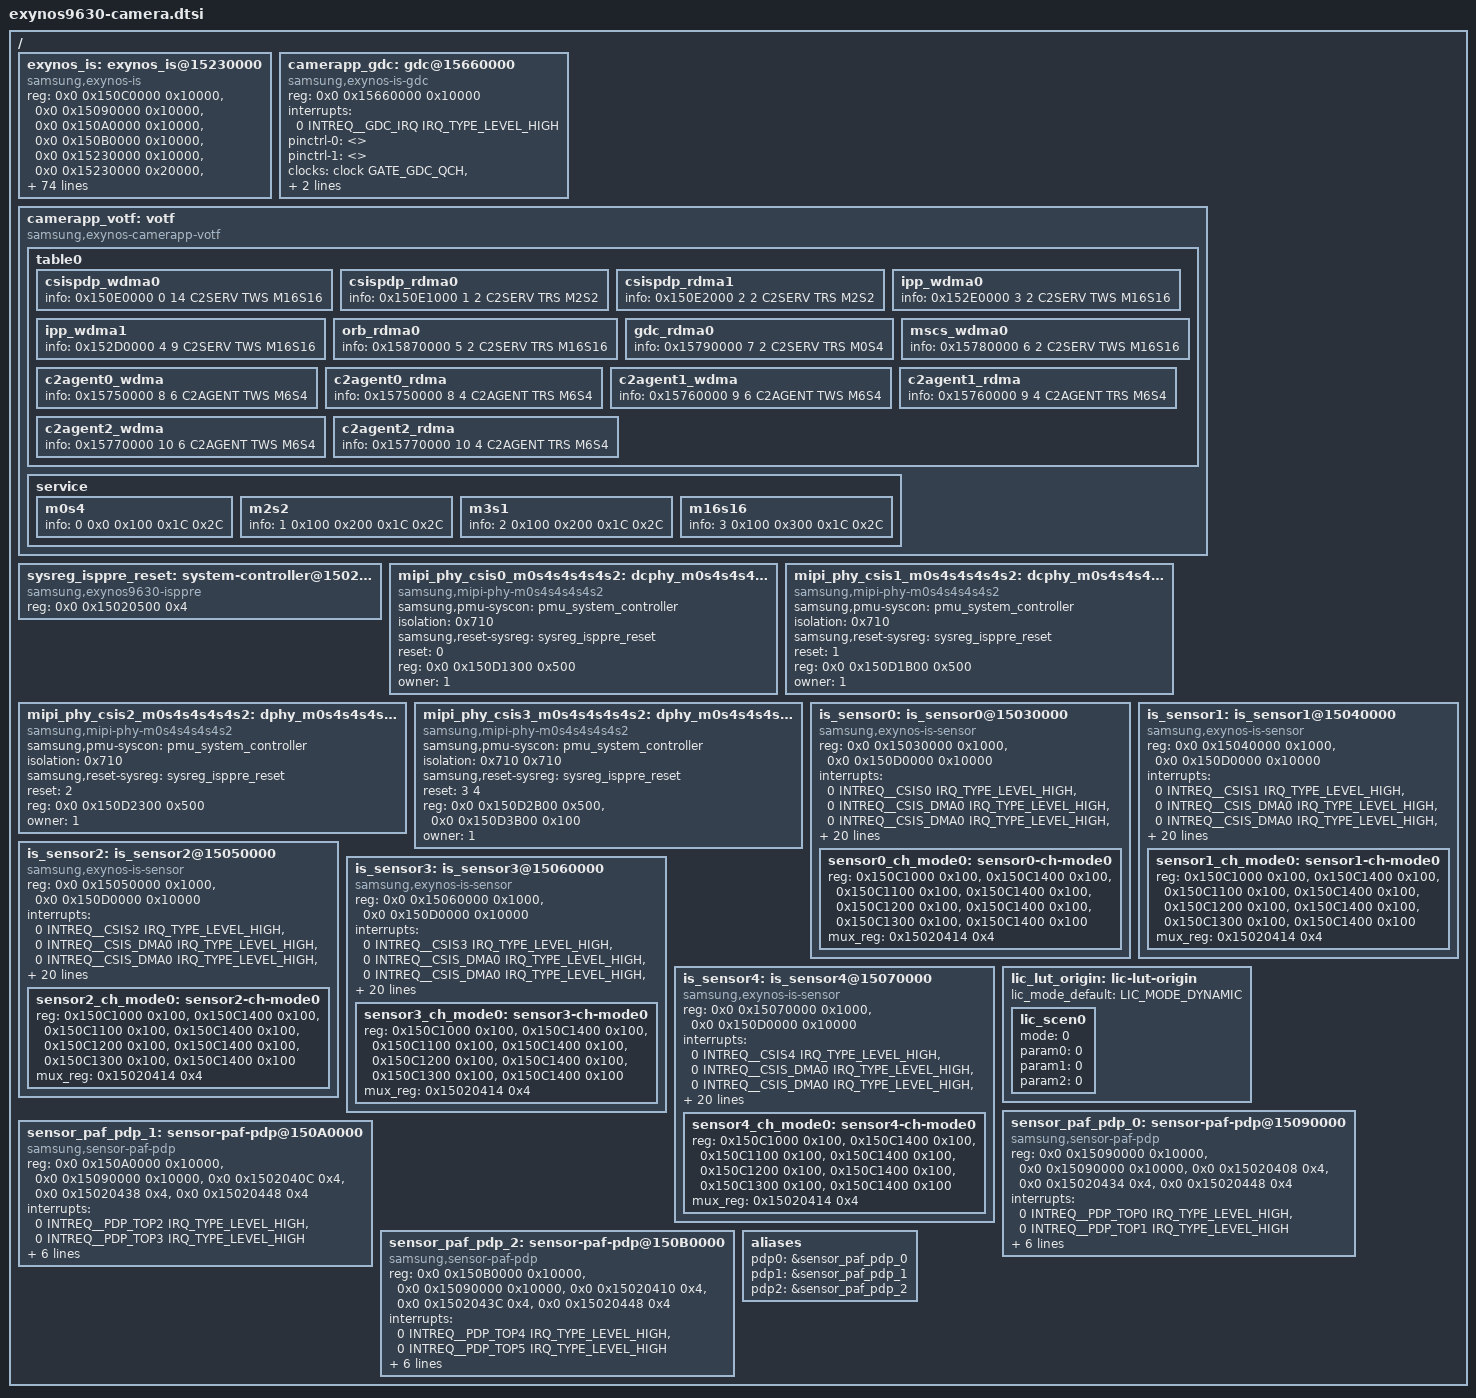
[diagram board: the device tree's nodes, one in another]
/*
 * SAMSUNG EXYNOS9630 SoC camera device tree source
 *
 * Copyright (c) 2019 Samsung Electronics Co., Ltd.
 *		http://www.samsung.com
 *
 * SAMSUNG EXYNOS9630 SoC camera device nodes are listed in this file.
 * EXYNOS9630 based board files can include this file and provide
 * values for board specfic bindings.
 *
 * This program is free software; you can redistribute it and/or modify
 * it under the terms of the GNU General Public License version 2 as
 * published by the Free Software Foundation.
 */

#include <dt-bindings/clock/exynos9630.h>
#include <dt-bindings/interrupt-controller/arm-gic.h>
#include <dt-bindings/interrupt-controller/exynos9630.h>
#include <dt-bindings/camera/exynos_is_dt.h>
#include "exynos9630-pinctrl.dtsi"
#include "exynos9630-sysmmu.dtsi"
#include <dt-bindings/camera/votf.h>

/ {
	exynos_is: exynos_is@15230000 {
		compatible = "samsung,exynos-is";
		reg = <0x0 0x150C0000 0x10000>, /* CSIS DMA  */
			<0x0 0x15090000 0x10000>, /* PDP CORE0 */
			<0x0 0x150A0000 0x10000>, /* PDP CORE1 */
			<0x0 0x150B0000 0x10000>, /* PDP CORE2 */
			<0x0 0x15230000 0x10000>, /* IPP0 */
			<0x0 0x15230000 0x20000>, /* IPP1 */
			<0x0 0x15230000 0x30000>, /* IPP2 */
			<0x0 0x150C0000 0x10000>, /* ZSL/STRIP DMA  */
			<0x0 0x15860000 0x10000>, /* ORBMCH */
			<0x0 0x15430000 0x10000>, /* ITP0 */
			<0x0 0x15840000 0x10000>, /* TNR */
			<0x0 0x15530000 0x10000>, /* DNS0 */
			<0x0 0x15640000 0x10000>, /* MCSC */
			<0x0 0x15360000 0x10000>; /* CLAHE */
		interrupts = <0 INTREQ__IPP_CH0_0 IRQ_TYPE_LEVEL_HIGH>,	/* IPP0_0 */
			<0 INTREQ__IPP_CH0_1 IRQ_TYPE_LEVEL_HIGH>,			/* IPP0_1 */
			<0 INTREQ__ORBMCH IRQ_TYPE_LEVEL_HIGH>,				/* ORBMCH */
			<0 INTREQ__ZSL_DMA0 IRQ_TYPE_LEVEL_HIGH>,				/* ZSL_DMA_0 */
			<0 INTREQ__STRP_DMA0 IRQ_TYPE_LEVEL_HIGH>,			/* STRIP_DMA_0 */
			<0 INTREQ__IPP_CH1_0 IRQ_TYPE_LEVEL_HIGH>,			/* IPP1_0 */
			<0 INTREQ__IPP_CH1_1 IRQ_TYPE_LEVEL_HIGH>,			/* IPP1_1 */
			<0 INTREQ__ORBMCH IRQ_TYPE_LEVEL_HIGH>,				/* ORBMCH */
			<0 INTREQ__ZSL_DMA1 IRQ_TYPE_LEVEL_HIGH>,				/* ZSL_DMA_1 */
			<0 INTREQ__STRP_DMA1 IRQ_TYPE_LEVEL_HIGH>,			/* STRIP_DMA_1 */
			<0 INTREQ__IPP_CH2_0 IRQ_TYPE_LEVEL_HIGH>,			/* IPP2_0 */
			<0 INTREQ__IPP_CH2_1 IRQ_TYPE_LEVEL_HIGH>,			/* IPP2_1 */
			<0 INTREQ__ZSL_DMA2 IRQ_TYPE_LEVEL_HIGH>,				/* ZSL_DMA_2 */
			<0 INTREQ__STRP_DMA2 IRQ_TYPE_LEVEL_HIGH>,			/* STRIP_DMA_2 */
			<0 INTREQ__DNS0_0 IRQ_TYPE_LEVEL_HIGH>,				/* ITP0_0 */
			<0 INTREQ__DNS0_1 IRQ_TYPE_LEVEL_HIGH>,				/* ITP0_1 */
			<0 INTREQ__TNR IRQ_TYPE_LEVEL_HIGH>,				/* TNR */
			<0 INTREQ__MCSC_OTF0 IRQ_TYPE_LEVEL_HIGH>,			/* MC_SC_0 */
			<0 INTREQ__CLAHE IRQ_TYPE_LEVEL_HIGH>;			/* CLAHE_0 */
		pinctrl-names = "default","release";
		pinctrl-0 = <>;
		pinctrl-1 = <>;
		clocks = <&clock GATE_SIPU_IPP_QCH>,
			<&clock GATE_SIPU_IPP_QCH_C2_STAT>,
			<&clock GATE_SIPU_IPP_QCH_C2_YDS>,

			<&clock GATE_TNR_QCH>,
			<&clock GATE_DNS_QCH>,
			<&clock GATE_ITP_QCH>,
			<&clock GATE_ORBMCH_QCH_ACLK>,
			<&clock GATE_ORBMCH_QCH_C2CLK>,

			<&clock GATE_GDC_QCH>,
			<&clock GATE_MCSC_QCH>,
			<&clock GATE_MCSC_CMU_MCSC_QCH>,
			<&clock GATE_GDC_QCH_C2>,
			<&clock GATE_MCSC_QCH_C2>,
			<&clock GATE_C2AGENT_D0_MCSC_QCH>,
			<&clock GATE_C2AGENT_D1_MCSC_QCH>,
			<&clock GATE_C2AGENT_D2_MCSC_QCH>,

			<&clock GATE_VRA_QCH>,
			<&clock UMUX_CLKCMU_VRA_BUS_USER>,
			<&clock UMUX_CLKCMU_VRA_CLAHE_USER>,
			<&clock GATE_CLAHE_QCH>,
			<&clock DOUT_CLK_VRA_BUSP>,

			<&clock CIS_CLK0>,
			<&clock CIS_CLK1>,
			<&clock CIS_CLK2>,
			<&clock CIS_CLK3>,
			<&clock CIS_CLK4>,

			<&clock GATE_DFTMUX_TOP_QCH_CIS_CLK0>,
			<&clock GATE_DFTMUX_TOP_QCH_CIS_CLK1>,
			<&clock GATE_DFTMUX_TOP_QCH_CIS_CLK2>,
			<&clock GATE_DFTMUX_TOP_QCH_CIS_CLK3>,
			<&clock GATE_DFTMUX_TOP_QCH_CIS_CLK4>,

			<&clock GATE_CSIS_PDP_QCH_C2_CSIS>,
			<&clock GATE_CSIS_PDP_QCH_CSIS0>,
			<&clock GATE_CSIS_PDP_QCH_CSIS1>,
			<&clock GATE_CSIS_PDP_QCH_CSIS2>,
			<&clock GATE_CSIS_PDP_QCH_CSIS3>,
			<&clock GATE_CSIS_PDP_QCH_CSIS4>,
			<&clock GATE_CSIS_PDP_QCH_CSIS_DMA>,
			<&clock GATE_CSIS_PDP_QCH_PDP_TOP>;
		clock-names = "GATE_SIPU_IPP_QCH",
			"GATE_SIPU_IPP_QCH_C2_STAT",
			"GATE_SIPU_IPP_QCH_C2_YDS",

			"GATE_TNR_QCH",
			"GATE_DNS_QCH",
			"GATE_ITP_QCH",
			"GATE_ORBMCH_QCH_ACLK",
			"GATE_ORBMCH_QCH_C2CLK",

			"GATE_GDC_QCH",
			"GATE_MCSC_QCH",
			"GATE_MCSC_CMU_MCSC_QCH",
			"GATE_GDC_QCH_C2",
			"GATE_MCSC_QCH_C2",
			"GATE_C2AGENT_D0_MCSC_QCH",
			"GATE_C2AGENT_D1_MCSC_QCH",
			"GATE_C2AGENT_D2_MCSC_QCH",

			"GATE_VRA_QCH",
			"UMUX_CLKCMU_VRA_BUS_USER",
			"UMUX_CLKCMU_VRA_CLAHE_USER",
			"GATE_CLAHE_QCH",
			"DOUT_CLK_VRA_BUSP",

			"CIS_CLK0",
			"CIS_CLK1",
			"CIS_CLK2",
			"CIS_CLK3",
			"CIS_CLK4",

			"GATE_DFTMUX_TOP_QCH_CIS_CLK0",
			"GATE_DFTMUX_TOP_QCH_CIS_CLK1",
			"GATE_DFTMUX_TOP_QCH_CIS_CLK2",
			"GATE_DFTMUX_TOP_QCH_CIS_CLK3",
			"GATE_DFTMUX_TOP_QCH_CIS_CLK4",

			"GATE_CSIS_PDP_QCH_C2_CSIS",
			"GATE_CSIS_PDP_QCH_CSIS0",
			"GATE_CSIS_PDP_QCH_CSIS1",
			"GATE_CSIS_PDP_QCH_CSIS2",
			"GATE_CSIS_PDP_QCH_CSIS3",
			"GATE_CSIS_PDP_QCH_CSIS4",
			"GATE_CSIS_PDP_QCH_CSIS_DMA",
			"GATE_CSIS_PDP_QCH_PDP_TOP";
		status = "ok";
		iommus = <&sysmmu_csis0>, <&sysmmu_csis1>, <&sysmmu_ipp>,
			<&sysmmu_tnr0>, <&sysmmu_tnr1>, <&sysmmu_dns>,
			<&sysmmu_mcsc0>, <&sysmmu_mcsc1>, <&sysmmu_vra>;
		#cooling-cells = <2>; /* min followed by max */
		/* ewf-index = <EWF_CMU_BUSC>; */
		list-scen-bts = "camera_default";
		num_of_3aa = <3>;
		num_of_isp = <1>;
		num_of_mcsc = <1>;
		num_of_vra = <0>;
		num_of_clh = <1>;
	};

	camerapp_gdc: gdc@15660000 {
		compatible = "samsung,exynos-is-gdc";
		reg = <0x0 0x15660000 0x10000>; /* GDC */
		interrupts = <0 INTREQ__GDC_IRQ IRQ_TYPE_LEVEL_HIGH>; /* GDC */
		pinctrl-names = "default","release";
		pinctrl-0 = <>;
		pinctrl-1 = <>;
		clocks = <&clock GATE_GDC_QCH>,
			<&clock GATE_GDC_QCH_C2>;
		clock-names = "gate",
			"gate2";
		status = "okay";
		iommus = <&sysmmu_mcsc0>;
		#cooling-cells = <2>; /* min followed by max */
	};

	camerapp_votf: votf {
		compatible = "samsung,exynos-camerapp-votf";
		status = "okay";

		table0 {
			/* base address, ip num, id cnt, C2SERV/C2AGENT, TWS/TRS, module type */
			csispdp_wdma0 { info = <0x150E0000 0 14 C2SERV TWS M16S16>; };
			csispdp_rdma0 { info = <0x150E1000 1 2 C2SERV TRS M2S2>; };
			csispdp_rdma1 { info = <0x150E2000 2 2 C2SERV TRS M2S2>; };

			ipp_wdma0 { info= <0x152E0000 3 2 C2SERV TWS M16S16>; };
			ipp_wdma1 { info = <0x152D0000 4 9 C2SERV TWS M16S16>; };

			orb_rdma0 { info = <0x15870000 5 2 C2SERV TRS M16S16>; };

			gdc_rdma0 { info = <0x15790000 7 2 C2SERV TRS M0S4>; };
			mscs_wdma0 { info = <0x15780000 6 2 C2SERV TWS M16S16>; };

			c2agent0_wdma { info = < 0x15750000 8 6 C2AGENT TWS M6S4>; };
			c2agent0_rdma { info = < 0x15750000 8 4 C2AGENT TRS M6S4>; };
			c2agent1_wdma { info = < 0x15760000 9 6 C2AGENT TWS M6S4>; };
			c2agent1_rdma { info = < 0x15760000 9 4 C2AGENT TRS M6S4>; };
			c2agent2_wdma { info = < 0x15770000 10 6 C2AGENT TWS M6S4>; };
			c2agent2_rdma { info = < 0x15770000 10 4 C2AGENT TRS M6S4>; };
		};

		service {
			/* num, tws addr, trs addr, tws gap, trs gap */
			m0s4 { info = <0 0x0 0x100 0x1C 0x2C>; };
			m2s2 { info = <1 0x100 0x200 0x1C 0x2C>; };
			m3s1 { info = <2 0x100 0x200 0x1C 0x2C>; };
			m16s16 { info = <3 0x100 0x300 0x1C 0x2C>; };
		};
	};

	sysreg_isppre_reset: system-controller@15020500 {
		compatible = "samsung,exynos9630-isppre", "syscon";
		reg = <0x0 0x15020500 0x4>;
	};

	mipi_phy_csis0_m0s4s4s4s4s2: dcphy_m0s4s4s4s4s2_csi0@15020500 {
		/* DPHY 6.5 Gbps 4lane */
		/* CPHY 2.5 Gbps 3lane */
		compatible = "samsung,mipi-phy-m0s4s4s4s4s2";
		samsung,pmu-syscon = <&pmu_system_controller>;
		isolation = <0x710>; /* PMU address offset */
		samsung,reset-sysreg = <&sysreg_isppre_reset>;
		reset = <0>; /* reset bit */
		reg = <0x0 0x150D1300 0x500>;
		owner = <1>; /* 0: DSI,  1: CSI */
		#phy-cells = <1>;
	};

	mipi_phy_csis1_m0s4s4s4s4s2: dcphy_m0s4s4s4s4s2_csi1@15020500 {
		/* DPHY 6.5 Gbps 4lane */
		/* CPHY 2.5 Gbps 3lane */
		compatible = "samsung,mipi-phy-m0s4s4s4s4s2";
		samsung,pmu-syscon = <&pmu_system_controller>;
		isolation = <0x710>; /* PMU address offset */
		samsung,reset-sysreg = <&sysreg_isppre_reset>;
		reset = <1>; /* reset bit */
		reg = <0x0 0x150D1B00 0x500>;
		owner = <1>; /* 0: DSI,  1: CSI */
		#phy-cells = <1>;
	};

	mipi_phy_csis2_m0s4s4s4s4s2: dphy_m0s4s4s4s4s2_csi2@15020500 {
		/* DPHY 6.5 Gbps 4lane */
		compatible = "samsung,mipi-phy-m0s4s4s4s4s2";
		samsung,pmu-syscon = <&pmu_system_controller>;
		isolation = <0x710>; /* PMU address offset */
		samsung,reset-sysreg = <&sysreg_isppre_reset>;
		reset = <2>; /* reset bit */
		reg = <0x0 0x150D2300 0x500>;
		owner = <1>; /* 0: DSI,  1: CSI */
		#phy-cells = <1>;
	};

	mipi_phy_csis3_m0s4s4s4s4s2: dphy_m0s4s4s4s4s2_csi3@15020500 {
		/* DPHY 2.5 Gbps 4lane or DPHY 2.5 Gbps 2lane */
		compatible = "samsung,mipi-phy-m0s4s4s4s4s2";
		samsung,pmu-syscon = <&pmu_system_controller>;
		isolation = <0x710 0x710>; /* PMU address offset */
		samsung,reset-sysreg = <&sysreg_isppre_reset>;
		reset = <3 4>; /* reset bit */
		reg = <0x0 0x150D2B00 0x500>,
			<0x0 0x150D3B00 0x100>;
		owner = <1>; /* 0: DSI,  1: CSI */
		#phy-cells = <1>;
	};

	is_sensor0: is_sensor0@15030000 {
		/* CSIS0 */
		compatible = "samsung,exynos-is-sensor";
		#address-cells = <1>;
		#size-cells = <1>;
		reg = <0x0 0x15030000 0x1000>, /* MIPI-CSI0 */
			<0x0 0x150D0000 0x10000>; /* PHY: M0S4S4S4S4S2 */
		reg-names = "csi", "phy";
		interrupts = <0 INTREQ__CSIS0 IRQ_TYPE_LEVEL_HIGH>, /*MIPI-CSI0 */
			<0 INTREQ__CSIS_DMA0 IRQ_TYPE_LEVEL_HIGH>,
			<0 INTREQ__CSIS_DMA0 IRQ_TYPE_LEVEL_HIGH>,
			<0 INTREQ__CSIS_DMA0 IRQ_TYPE_LEVEL_HIGH>,
			<0 INTREQ__CSIS_DMA0 IRQ_TYPE_LEVEL_HIGH>;
		interrupt-names = "csi",
			"mode0_VC0", "mode0_VC1","mode0_VC2","mode0_VC3";
		phys = <&mipi_phy_csis0_m0s4s4s4s4s2 0>;
		phy-names = "csis_dphy";
		clocks = <&clock CIS_CLK0>,
			<&clock CIS_CLK1>,
			<&clock CIS_CLK2>,
			<&clock CIS_CLK3>,
			<&clock CIS_CLK4>,

			<&clock GATE_DFTMUX_TOP_QCH_CIS_CLK0>,
			<&clock GATE_DFTMUX_TOP_QCH_CIS_CLK1>,
			<&clock GATE_DFTMUX_TOP_QCH_CIS_CLK2>,
			<&clock GATE_DFTMUX_TOP_QCH_CIS_CLK3>,
			<&clock GATE_DFTMUX_TOP_QCH_CIS_CLK4>,

			<&clock GATE_CSIS_PDP_QCH_C2_CSIS>,
			<&clock GATE_CSIS_PDP_QCH_CSIS0>,
			<&clock GATE_CSIS_PDP_QCH_CSIS1>,
			<&clock GATE_CSIS_PDP_QCH_CSIS2>,
			<&clock GATE_CSIS_PDP_QCH_CSIS3>,
			<&clock GATE_CSIS_PDP_QCH_CSIS4>,
			<&clock GATE_CSIS_PDP_QCH_CSIS_DMA>,
			<&clock GATE_CSIS_PDP_QCH_PDP_TOP>;
		clock-names = "CIS_CLK0",
			"CIS_CLK1",
			"CIS_CLK2",
			"CIS_CLK3",
			"CIS_CLK4",

			"GATE_DFTMUX_TOP_QCH_CIS_CLK0",
			"GATE_DFTMUX_TOP_QCH_CIS_CLK1",
			"GATE_DFTMUX_TOP_QCH_CIS_CLK2",
			"GATE_DFTMUX_TOP_QCH_CIS_CLK3",
			"GATE_DFTMUX_TOP_QCH_CIS_CLK4",

			"GATE_CSIS_PDP_QCH_C2_CSIS",
			"GATE_CSIS_PDP_QCH_CSIS0",
			"GATE_CSIS_PDP_QCH_CSIS1",
			"GATE_CSIS_PDP_QCH_CSIS2",
			"GATE_CSIS_PDP_QCH_CSIS3",
			"GATE_CSIS_PDP_QCH_CSIS4",
			"GATE_CSIS_PDP_QCH_CSIS_DMA",
			"GATE_CSIS_PDP_QCH_PDP_TOP";
		iommus = <&sysmmu_csis0>, <&sysmmu_csis1>;

		/* without PAF HW */
		sensor0_ch_mode0: sensor0-ch-mode0 {
			reg = <0x150C1000 0x100>, /* DMA0 VC0 */
				<0x150C1400 0x100>, /* DMA0 Common */
				<0x150C1100 0x100>, /* DMA0 VC1 */
				<0x150C1400 0x100>, /* DMA0 Common */
				<0x150C1200 0x100>, /* DMA0 VC2 */
				<0x150C1400 0x100>, /* DMA0 Common */
				<0x150C1300 0x100>, /* DMA0 VC3 */
				<0x150C1400 0x100>; /* DMA0 Common */
			mux_reg = <0x15020414 0x4>; /* DMA0 input mux */
		};
	};

	is_sensor1: is_sensor1@15040000 {
		/* CSIS1 */
		compatible = "samsung,exynos-is-sensor";
		#address-cells = <1>;
		#size-cells = <1>;
		reg = <0x0 0x15040000 0x1000>, /* MIPI-CSI1 */
			<0x0 0x150D0000 0x10000>; /* PHY: M0S4S4S4S4S2 */
		reg-names = "csi", "phy";
		interrupts = <0 INTREQ__CSIS1 IRQ_TYPE_LEVEL_HIGH>, /* MIPI-CSI1 */
			<0 INTREQ__CSIS_DMA0 IRQ_TYPE_LEVEL_HIGH>,
			<0 INTREQ__CSIS_DMA0 IRQ_TYPE_LEVEL_HIGH>,
			<0 INTREQ__CSIS_DMA0 IRQ_TYPE_LEVEL_HIGH>,
			<0 INTREQ__CSIS_DMA0 IRQ_TYPE_LEVEL_HIGH>;
		interrupt-names = "csi",
			"mode0_VC0", "mode0_VC1","mode0_VC2","mode0_VC3";
		phys = <&mipi_phy_csis1_m0s4s4s4s4s2 0>;
		phy-names = "csis_dphy";
		clocks = <&clock CIS_CLK0>,
			<&clock CIS_CLK1>,
			<&clock CIS_CLK2>,
			<&clock CIS_CLK3>,
			<&clock CIS_CLK4>,

			<&clock GATE_DFTMUX_TOP_QCH_CIS_CLK0>,
			<&clock GATE_DFTMUX_TOP_QCH_CIS_CLK1>,
			<&clock GATE_DFTMUX_TOP_QCH_CIS_CLK2>,
			<&clock GATE_DFTMUX_TOP_QCH_CIS_CLK3>,
			<&clock GATE_DFTMUX_TOP_QCH_CIS_CLK4>,

			<&clock GATE_CSIS_PDP_QCH_C2_CSIS>,
			<&clock GATE_CSIS_PDP_QCH_CSIS0>,
			<&clock GATE_CSIS_PDP_QCH_CSIS1>,
			<&clock GATE_CSIS_PDP_QCH_CSIS2>,
			<&clock GATE_CSIS_PDP_QCH_CSIS3>,
			<&clock GATE_CSIS_PDP_QCH_CSIS4>,
			<&clock GATE_CSIS_PDP_QCH_CSIS_DMA>,
			<&clock GATE_CSIS_PDP_QCH_PDP_TOP>;
		clock-names = "CIS_CLK0",
			"CIS_CLK1",
			"CIS_CLK2",
			"CIS_CLK3",
			"CIS_CLK4",

			"GATE_DFTMUX_TOP_QCH_CIS_CLK0",
			"GATE_DFTMUX_TOP_QCH_CIS_CLK1",
			"GATE_DFTMUX_TOP_QCH_CIS_CLK2",
			"GATE_DFTMUX_TOP_QCH_CIS_CLK3",
			"GATE_DFTMUX_TOP_QCH_CIS_CLK4",

			"GATE_CSIS_PDP_QCH_C2_CSIS",
			"GATE_CSIS_PDP_QCH_CSIS0",
			"GATE_CSIS_PDP_QCH_CSIS1",
			"GATE_CSIS_PDP_QCH_CSIS2",
			"GATE_CSIS_PDP_QCH_CSIS3",
			"GATE_CSIS_PDP_QCH_CSIS4",
			"GATE_CSIS_PDP_QCH_CSIS_DMA",
			"GATE_CSIS_PDP_QCH_PDP_TOP";
		iommus = <&sysmmu_csis0>, <&sysmmu_csis1>;

		/* without PAF HW */
		sensor1_ch_mode0: sensor1-ch-mode0 {
			reg = <0x150C1000 0x100>, /* DMA0 VC0 */
				<0x150C1400 0x100>, /* DMA0 Common */
				<0x150C1100 0x100>, /* DMA0 VC1 */
				<0x150C1400 0x100>, /* DMA0 Common */
				<0x150C1200 0x100>, /* DMA0 VC2 */
				<0x150C1400 0x100>, /* DMA0 Common */
				<0x150C1300 0x100>, /* DMA0 VC3 */
				<0x150C1400 0x100>; /* DMA0 Common */
			mux_reg = <0x15020414 0x4>; /* DMA0 input mux */
		};
	};

	is_sensor2: is_sensor2@15050000 {
		/* CSIS2 */
		compatible = "samsung,exynos-is-sensor";
		#address-cells = <1>;
		#size-cells = <1>;
		reg = <0x0 0x15050000 0x1000>, /* MIPI-CSI2 */
			<0x0 0x150D0000 0x10000>; /* PHY: M0S4S4S4S4S2 */
		reg-names = "csi", "phy";
		interrupts = <0 INTREQ__CSIS2 IRQ_TYPE_LEVEL_HIGH>, /* MIPI-CSI2 */
			<0 INTREQ__CSIS_DMA0 IRQ_TYPE_LEVEL_HIGH>,
			<0 INTREQ__CSIS_DMA0 IRQ_TYPE_LEVEL_HIGH>,
			<0 INTREQ__CSIS_DMA0 IRQ_TYPE_LEVEL_HIGH>,
			<0 INTREQ__CSIS_DMA0 IRQ_TYPE_LEVEL_HIGH>;
		interrupt-names = "csi",
			"mode0_VC0", "mode0_VC1","mode0_VC2","mode0_VC3";
		phys = <&mipi_phy_csis2_m0s4s4s4s4s2 0>;
		phy-names = "csis_dphy";
		clocks = <&clock CIS_CLK0>,
			<&clock CIS_CLK1>,
			<&clock CIS_CLK2>,
			<&clock CIS_CLK3>,
			<&clock CIS_CLK4>,

			<&clock GATE_DFTMUX_TOP_QCH_CIS_CLK0>,
			<&clock GATE_DFTMUX_TOP_QCH_CIS_CLK1>,
			<&clock GATE_DFTMUX_TOP_QCH_CIS_CLK2>,
			<&clock GATE_DFTMUX_TOP_QCH_CIS_CLK3>,
			<&clock GATE_DFTMUX_TOP_QCH_CIS_CLK4>,

			<&clock GATE_CSIS_PDP_QCH_C2_CSIS>,
			<&clock GATE_CSIS_PDP_QCH_CSIS0>,
			<&clock GATE_CSIS_PDP_QCH_CSIS1>,
			<&clock GATE_CSIS_PDP_QCH_CSIS2>,
			<&clock GATE_CSIS_PDP_QCH_CSIS3>,
			<&clock GATE_CSIS_PDP_QCH_CSIS4>,
			<&clock GATE_CSIS_PDP_QCH_CSIS_DMA>,
			<&clock GATE_CSIS_PDP_QCH_PDP_TOP>;
		clock-names = "CIS_CLK0",
			"CIS_CLK1",
			"CIS_CLK2",
			"CIS_CLK3",
			"CIS_CLK4",

			"GATE_DFTMUX_TOP_QCH_CIS_CLK0",
			"GATE_DFTMUX_TOP_QCH_CIS_CLK1",
			"GATE_DFTMUX_TOP_QCH_CIS_CLK2",
			"GATE_DFTMUX_TOP_QCH_CIS_CLK3",
			"GATE_DFTMUX_TOP_QCH_CIS_CLK4",

			"GATE_CSIS_PDP_QCH_C2_CSIS",
			"GATE_CSIS_PDP_QCH_CSIS0",
			"GATE_CSIS_PDP_QCH_CSIS1",
			"GATE_CSIS_PDP_QCH_CSIS2",
			"GATE_CSIS_PDP_QCH_CSIS3",
			"GATE_CSIS_PDP_QCH_CSIS4",
			"GATE_CSIS_PDP_QCH_CSIS_DMA",
			"GATE_CSIS_PDP_QCH_PDP_TOP";
		iommus = <&sysmmu_csis0>, <&sysmmu_csis1>;

		/* without PAF HW */
		sensor2_ch_mode0: sensor2-ch-mode0 {
			reg = <0x150C1000 0x100>, /* DMA0 VC0 */
				<0x150C1400 0x100>, /* DMA0 Common */
				<0x150C1100 0x100>, /* DMA0 VC1 */
				<0x150C1400 0x100>, /* DMA0 Common */
				<0x150C1200 0x100>, /* DMA0 VC2 */
				<0x150C1400 0x100>, /* DMA0 Common */
				<0x150C1300 0x100>, /* DMA0 VC3 */
				<0x150C1400 0x100>; /* DMA0 Common */
			mux_reg = <0x15020414 0x4>; /* DMA0 input mux */
		};
	};

	is_sensor3: is_sensor3@15060000 {
		/* CSIS3 */
		compatible = "samsung,exynos-is-sensor";
		#address-cells = <1>;
		#size-cells = <1>;
		#interrupt-cells = <1>;
		reg = <0x0 0x15060000 0x1000>, /* MIPI-CSI3 */
			<0x0 0x150D0000 0x10000>; /* PHY: M0S4S4S4S4S2 */
		reg-names = "csi", "phy";
		interrupts = <0 INTREQ__CSIS3 IRQ_TYPE_LEVEL_HIGH>, /* MIPI-CSI3 */
			<0 INTREQ__CSIS_DMA0 IRQ_TYPE_LEVEL_HIGH>,
			<0 INTREQ__CSIS_DMA0 IRQ_TYPE_LEVEL_HIGH>,
			<0 INTREQ__CSIS_DMA0 IRQ_TYPE_LEVEL_HIGH>,
			<0 INTREQ__CSIS_DMA0 IRQ_TYPE_LEVEL_HIGH>;
		interrupt-names = "csi",
			"mode0_VC0", "mode0_VC1","mode0_VC2","mode0_VC3";
		phys = <&mipi_phy_csis3_m0s4s4s4s4s2 0>;
		phy-names = "csis_dphy";
		clocks = <&clock CIS_CLK0>,
			<&clock CIS_CLK1>,
			<&clock CIS_CLK2>,
			<&clock CIS_CLK3>,
			<&clock CIS_CLK4>,

			<&clock GATE_DFTMUX_TOP_QCH_CIS_CLK0>,
			<&clock GATE_DFTMUX_TOP_QCH_CIS_CLK1>,
			<&clock GATE_DFTMUX_TOP_QCH_CIS_CLK2>,
			<&clock GATE_DFTMUX_TOP_QCH_CIS_CLK3>,
			<&clock GATE_DFTMUX_TOP_QCH_CIS_CLK4>,

			<&clock GATE_CSIS_PDP_QCH_C2_CSIS>,
			<&clock GATE_CSIS_PDP_QCH_CSIS0>,
			<&clock GATE_CSIS_PDP_QCH_CSIS1>,
			<&clock GATE_CSIS_PDP_QCH_CSIS2>,
			<&clock GATE_CSIS_PDP_QCH_CSIS3>,
			<&clock GATE_CSIS_PDP_QCH_CSIS4>,
			<&clock GATE_CSIS_PDP_QCH_CSIS_DMA>,
			<&clock GATE_CSIS_PDP_QCH_PDP_TOP>;
		clock-names = "CIS_CLK0",
			"CIS_CLK1",
			"CIS_CLK2",
			"CIS_CLK3",
			"CIS_CLK4",

			"GATE_DFTMUX_TOP_QCH_CIS_CLK0",
			"GATE_DFTMUX_TOP_QCH_CIS_CLK1",
			"GATE_DFTMUX_TOP_QCH_CIS_CLK2",
			"GATE_DFTMUX_TOP_QCH_CIS_CLK3",
			"GATE_DFTMUX_TOP_QCH_CIS_CLK4",

			"GATE_CSIS_PDP_QCH_C2_CSIS",
			"GATE_CSIS_PDP_QCH_CSIS0",
			"GATE_CSIS_PDP_QCH_CSIS1",
			"GATE_CSIS_PDP_QCH_CSIS2",
			"GATE_CSIS_PDP_QCH_CSIS3",
			"GATE_CSIS_PDP_QCH_CSIS4",
			"GATE_CSIS_PDP_QCH_CSIS_DMA",
			"GATE_CSIS_PDP_QCH_PDP_TOP";
		iommus = <&sysmmu_csis0>, <&sysmmu_csis1>;

		/* without PAF HW */
		sensor3_ch_mode0: sensor3-ch-mode0 {
			reg = <0x150C1000 0x100>, /* DMA0 VC0 */
				<0x150C1400 0x100>, /* DMA0 Common */
				<0x150C1100 0x100>, /* DMA0 VC1 */
				<0x150C1400 0x100>, /* DMA0 Common */
				<0x150C1200 0x100>, /* DMA0 VC2 */
				<0x150C1400 0x100>, /* DMA0 Common */
				<0x150C1300 0x100>, /* DMA0 VC3 */
				<0x150C1400 0x100>; /* DMA0 Common */
			mux_reg = <0x15020414 0x4>; /* DMA0 input mux */
		};
	};

	is_sensor4: is_sensor4@15070000 {
		/* CSIS4 */
		compatible = "samsung,exynos-is-sensor";
		#address-cells = <1>;
		#size-cells = <1>;
		reg = <0x0 0x15070000 0x1000>, /* MIPI-CSI4 */
			<0x0 0x150D0000 0x10000>; /* PHY: M0S4S4S4S4S2 */
		reg-names = "csi", "phy";
		interrupts = <0 INTREQ__CSIS4 IRQ_TYPE_LEVEL_HIGH>, /* MIPI-CSI4 */
			<0 INTREQ__CSIS_DMA0 IRQ_TYPE_LEVEL_HIGH>,
			<0 INTREQ__CSIS_DMA0 IRQ_TYPE_LEVEL_HIGH>,
			<0 INTREQ__CSIS_DMA0 IRQ_TYPE_LEVEL_HIGH>,
			<0 INTREQ__CSIS_DMA0 IRQ_TYPE_LEVEL_HIGH>;
		interrupt-names = "csi",
			"mode0_VC0", "mode0_VC1","mode0_VC2","mode0_VC3";
		phys = <&mipi_phy_csis3_m0s4s4s4s4s2 1>;
		phy-names = "csis_dphy";
		clocks = <&clock CIS_CLK0>,
			<&clock CIS_CLK1>,
			<&clock CIS_CLK2>,
			<&clock CIS_CLK3>,
			<&clock CIS_CLK4>,

			<&clock GATE_DFTMUX_TOP_QCH_CIS_CLK0>,
			<&clock GATE_DFTMUX_TOP_QCH_CIS_CLK1>,
			<&clock GATE_DFTMUX_TOP_QCH_CIS_CLK2>,
			<&clock GATE_DFTMUX_TOP_QCH_CIS_CLK3>,
			<&clock GATE_DFTMUX_TOP_QCH_CIS_CLK4>,

			<&clock GATE_CSIS_PDP_QCH_C2_CSIS>,
			<&clock GATE_CSIS_PDP_QCH_CSIS0>,
			<&clock GATE_CSIS_PDP_QCH_CSIS1>,
			<&clock GATE_CSIS_PDP_QCH_CSIS2>,
			<&clock GATE_CSIS_PDP_QCH_CSIS3>,
			<&clock GATE_CSIS_PDP_QCH_CSIS4>,
			<&clock GATE_CSIS_PDP_QCH_CSIS_DMA>,
			<&clock GATE_CSIS_PDP_QCH_PDP_TOP>;
		clock-names = "CIS_CLK0",
			"CIS_CLK1",
			"CIS_CLK2",
			"CIS_CLK3",
			"CIS_CLK4",

			"GATE_DFTMUX_TOP_QCH_CIS_CLK0",
			"GATE_DFTMUX_TOP_QCH_CIS_CLK1",
			"GATE_DFTMUX_TOP_QCH_CIS_CLK2",
			"GATE_DFTMUX_TOP_QCH_CIS_CLK3",
			"GATE_DFTMUX_TOP_QCH_CIS_CLK4",

			"GATE_CSIS_PDP_QCH_C2_CSIS",
			"GATE_CSIS_PDP_QCH_CSIS0",
			"GATE_CSIS_PDP_QCH_CSIS1",
			"GATE_CSIS_PDP_QCH_CSIS2",
			"GATE_CSIS_PDP_QCH_CSIS3",
			"GATE_CSIS_PDP_QCH_CSIS4",
			"GATE_CSIS_PDP_QCH_CSIS_DMA",
			"GATE_CSIS_PDP_QCH_PDP_TOP";
		iommus = <&sysmmu_csis0>, <&sysmmu_csis1>;

		/* without PAF HW */
		sensor4_ch_mode0: sensor4-ch-mode0 {
			reg = <0x150C1000 0x100>, /* DMA0 VC0 */
				<0x150C1400 0x100>, /* DMA0 Common */
				<0x150C1100 0x100>, /* DMA0 VC1 */
				<0x150C1400 0x100>, /* DMA0 Common */
				<0x150C1200 0x100>, /* DMA0 VC2 */
				<0x150C1400 0x100>, /* DMA0 Common */
				<0x150C1300 0x100>, /* DMA0 VC3 */
				<0x150C1400 0x100>; /* DMA0 Common */
			mux_reg = <0x15020414 0x4>; /* DMA0 input mux */
		};
	};

	lic_lut_origin: lic-lut-origin {
		#define LIC_MODE_DYNAMIC	(0)
		#define LIC_MODE_STATIC		(1)
		#define LIC_PATH_OTF		(0)
		#define LIC_PATH_DMA		(1)

		lic_mode_default = <LIC_MODE_DYNAMIC>;

		/*
		 * When DYNAMIC mode is selected, param means enable limitation for DMA path.
		 * Example:
		 * @ mode = <LIC_MODE_DYNAMIC>;
		 * @ param0 = <LIC_PATH_OTF>;
		 * @ param1 = <LIC_PATH_DMA>;
		 * @ param2 = <LIC_PATH_OTF>;
		 *
		 * When STATIC mode is selected, param means buffer size for each context.
		 * Example:
		 * @ mode = <LIC_MODE_STAIC>;
		 * @ param0 = <3584>;
		 * @ param1 = <3583>;
		 * @ param2 = <1>;
		 *
		 * The lic_scen0 is not abailable. If the index of LUT is "0", the selection is skipped.
		 */
		lic_scen0 { /* Reserved */
			mode = <0>;
			param0 = <0>;
			param1 = <0>;
			param2 = <0>;
		};
	};

	sensor_paf_pdp_0: sensor-paf-pdp@15090000 {
		/* PDP CORE0 */
		compatible = "samsung,sensor-paf-pdp";
		reg = <0x0 0x15090000 0x10000>, /* PDP CORE0 */
			<0x0 0x15090000 0x10000>, /* PDP CORE0: For common regiser */
			<0x0 0x15020408 0x4>, /* PDP input mux(CSIS_PDP_SC_CON0) in SYSREG */
			<0x0 0x15020434 0x4>, /* PDP input vc mux(CSIS_PDP_VC_CON0) in SYSREG */
			<0x0 0x15020448 0x4>; /* CSIS_PDP_SC_PDP_IN_EN in SYSREG */
		reg-names = "core", "common", "mux", "vc_mux", "en";
		interrupts = <0 INTREQ__PDP_TOP0 IRQ_TYPE_LEVEL_HIGH>,
			<0 INTREQ__PDP_TOP1 IRQ_TYPE_LEVEL_HIGH>;
		mux =  <0 1 2 3 4>; /* <csi0 csi1 csi2 csi3 csi4> */
		vc_mux = <0x1 0x1 0x1 0x1 0x1>; /* <csi0 csi1 csi2 csi3 csi4> */
		en =  <0 1 2 3 4>; /* bit postion: <csi0 csi1 csi2 csi3 csi4> */
		leader; /* have RDMA & create video node */
		lic_lut = <&lic_lut_origin>;
		clocks = <&clock GATE_CSIS_PDP_QCH_PDP_TOP>;
		clock-names = "aclk";
	};

	sensor_paf_pdp_1: sensor-paf-pdp@150A0000 {
		/* PDP CORE1 */
		compatible = "samsung,sensor-paf-pdp";
		reg = <0x0 0x150A0000 0x10000>, /* PDP CORE1 */
			<0x0 0x15090000 0x10000>, /* PDP CORE0: For common regiser */
			<0x0 0x1502040C 0x4>, /* PDP input mux(CSIS_PDP_SC_CON1) in SYSREG */
			<0x0 0x15020438 0x4>, /* PDP input vc mux(CSIS_PDP_VC_CON1) in SYSREG */
			<0x0 0x15020448 0x4>; /* CSIS_PDP_SC_PDP_IN_EN in SYSREG */
		reg-names = "core", "common", "mux", "vc_mux", "en";
		interrupts = <0 INTREQ__PDP_TOP2 IRQ_TYPE_LEVEL_HIGH>,
			<0 INTREQ__PDP_TOP3 IRQ_TYPE_LEVEL_HIGH>;
		mux =  <0 1 2 3 4>; /* <csi0 csi1 csi2 csi3 csi4> */
		vc_mux = <0x1 0x1 0x1 0x1 0x1>; /* <csi0 csi1 csi2 csi3 csi4> */
		en =  <6 7 8 9 10>; /* bit postion: <csi0 csi1 csi2 csi3 csi4> */
		leader; /* have RDMA & create video node */
		lic_lut = <&lic_lut_origin>;
		clocks = <&clock GATE_CSIS_PDP_QCH_PDP_TOP>;
		clock-names = "aclk";
	};

	sensor_paf_pdp_2: sensor-paf-pdp@150B0000 {
		/* PDP CORE2 */
		compatible = "samsung,sensor-paf-pdp";
		reg = <0x0 0x150B0000 0x10000>, /* PDP CORE2 */
			<0x0 0x15090000 0x10000>, /* PDP CORE0: For common regiser */
			<0x0 0x15020410 0x4>, /* PDP input mux(CSIS_PDP_SC_CON2) in SYSREG */
			<0x0 0x1502043C 0x4>, /* PDP input vc mux(CSIS_PDP_VC_CON2) in SYSREG */
			<0x0 0x15020448 0x4>; /* CSIS_PDP_SC_PDP_IN_EN in SYSREG */
		reg-names = "core", "common", "mux", "vc_mux", "en";
		interrupts = <0 INTREQ__PDP_TOP4 IRQ_TYPE_LEVEL_HIGH>,
			<0 INTREQ__PDP_TOP5 IRQ_TYPE_LEVEL_HIGH>;
		mux =  <0 1 2 3 4>; /* <csi0 csi1 csi2 csi3 csi4> */
		vc_mux = <0x1 0x1 0x1 0x1 0x1>; /* <csi0 csi1 csi2 csi3 csi4> */
		en =  <12 13 14 15 16>; /* bit postion: <csi0 csi1 csi2 csi3 csi4> */
		leader; /* have RDMA & create video node */
		lic_lut = <&lic_lut_origin>;
		clocks = <&clock GATE_CSIS_PDP_QCH_PDP_TOP>;
		clock-names = "aclk";
	};

	aliases {
		pdp0 = &sensor_paf_pdp_0;
		pdp1 = &sensor_paf_pdp_1;
		pdp2 = &sensor_paf_pdp_2;
	};
};
